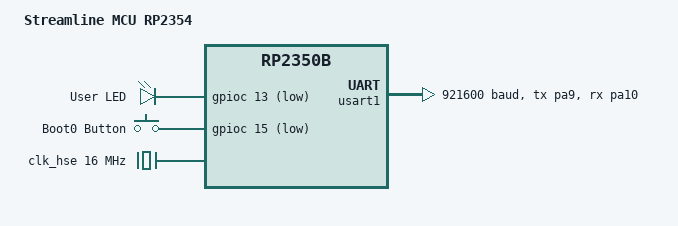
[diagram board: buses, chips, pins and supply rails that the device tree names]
/dts-v1/;
#include <raspberrypi/rpi_pico/rp2350b.dtsi>
#include "streamline_mcu_rp2354-pinctrl.dtsi"

/ {
	model = "Streamline MCU RP2354";
	compatible = "currentmakers,streamline-mcu-rp2354";

	chosen {
		zephyr,sram = &sram0;
		zephyr,flash = &flash0;

		zephyr,console = &usart1;
		zephyr,shell-uart = &usart1;
	};

	leds {
		compatible = "gpio-leds";

		user_led: led_0 {
			gpios = <&gpioc 13 GPIO_ACTIVE_LOW>;
			label = "User LED";
		};
	};

	buttons {
		compatible = "gpio-keys";

		boot_button: button_0 {
			gpios = <&gpioc 15 (GPIO_PULL_UP | GPIO_ACTIVE_LOW)>;
			label = "Boot0 Button";
		};
	};

	aliases {
		led0 = &user_led;
		sw0 = &boot_button;
	};
};

&flash0 {
	reg = <0x10000000 0x20000>;
};

/* Configure the External Crystal (HSE) */
&clk_hse {
	clock-frequency = <DT_FREQ_M(16)>; /* SET TO YOUR ACTUAL CRYSTAL FREQ */
	status = "okay";
};

&pll {
	div-m = <1>;
	mul-n = <10>;
	div-p = <7>;
	div-q = <2>;
	clocks = <&clk_hse>;
	status = "okay";
};

&pllsai1 {
	div-m = <1>;
	mul-n = <160>;
	div-p = <7>;
	div-q = <6>;
	clocks = <&clk_hse>;
	status = "okay";
};

&rcc {
	clocks = <&pll>;
	clock-frequency = <DT_FREQ_M(80)>;
	ahb-prescaler = <1>;
	apb1-prescaler = <1>;
	apb2-prescaler = <1>;
};

&usart1 {
	pinctrl-0 = <&usart1_tx_pa9 &usart1_rx_pa10>;
	pinctrl-names = "default";
	current-speed = <921600>;
	status = "okay";
};

